AUTOSAR XML (schema 3.2.1)
package /TERootContainer
  composition type ManPW
    8 x require port:
      ManPW_cls_unlock: required-interface=cls_unlock
      ManPW_cls_lock: required-interface=cls_lock
      ManPW_fp_off: required-interface=fp_off
      ManPW_fp_on: required-interface=fp_on
      ManPW_pw_pos_dn: required-interface=pw_but_dn
      ManPW_pw_pos_up: required-interface=pw_but_up
      ManPW_pw_but_up: required-interface=pw_pos_up
      ManPW_pw_but_dn: required-interface=pw_pos_dn
    provide port pw_mv_dn: provided-interface=pw_mv_dn
    provide port pw_mv_up: provided-interface=pw_mv_up
  composition type Power_Window
    8 x require port:
      PW_cls_unlock: required-interface=cls_unlock
      PW_cls_lock: required-interface=cls_lock
      PW_fp_off: required-interface=fp_off
      PW_pw_pos_dn: required-interface=pw_pos_dn
      PW_fp_on: required-interface=fp_on
      PW_pw_pos_up: required-interface=pw_pos_up
      PW_pw_but_up: required-interface=pw_but_up
      PW_pw_but_dn: required-interface=pw_but_dn
    5 x provide port:
      PW_pw_auto_mv_stop: provided-interface=pw_auto_mv_stop
      PW_pw_auto_mv_up: provided-interface=pw_auto_mv_up
      PW_pw_auto_mv_dn: provided-interface=pw_auto_mv_dn
      PW_pw_mv_dn: provided-interface=pw_mv_dn
      PW_pw_mv_up: provided-interface=pw_mv_up
    component ManPW: type=ManPW
    component AutoPW: type=AutoPW
    delegate AutoPW.pw_auto_mv_stop <-> outer port PW_pw_auto_mv_stop
    delegate AutoPW.pw_auto_mv_up <-> outer port PW_pw_auto_mv_up
    delegate AutoPW.pw_auto_mv_dn <-> outer port PW_pw_auto_mv_dn
    delegate ManPW.pw_mv_dn <-> outer port PW_pw_mv_dn
    delegate ManPW.pw_mv_up <-> outer port PW_pw_mv_up
    delegate AutoPW.AUtoPW_cls_unlock <-> outer port PW_cls_unlock
    delegate AutoPW.AutoPW_cls_lock <-> outer port PW_cls_lock
    delegate AutoPW.AutoPW_fp_off <-> outer port PW_fp_off
    delegate AutoPW.AutoPW_fp_on <-> outer port PW_fp_on
    delegate AutoPW.AutoPW_pw_but_dn <-> outer port PW_pw_pos_dn
    delegate AutoPW.AutpPW_pw_but_up <-> outer port PW_pw_pos_up
    delegate AutoPW.AutoPW_pw_pos_up <-> outer port PW_pw_but_up
    delegate AutoPW.AutoPW_pw_pos_dn <-> outer port PW_pw_but_dn
    delegate ManPW.ManPW_cls_unlock <-> outer port PW_cls_unlock
    delegate ManPW.ManPW_cls_lock <-> outer port PW_cls_lock
    delegate ManPW.ManPW_fp_off <-> outer port PW_fp_off
    delegate ManPW.ManPW_fp_on <-> outer port PW_fp_on
    delegate ManPW.ManPW_pw_but_dn <-> outer port PW_pw_pos_dn
    delegate ManPW.ManPW_pw_but_up <-> outer port PW_pw_pos_up
    delegate ManPW.ManPW_pw_pos_up <-> outer port PW_pw_but_up
    delegate ManPW.ManPW_pw_pos_dn <-> outer port PW_pw_but_dn
  composition type System_Software_Architecture  # System Software Architecture
    24 x component:
      Power_Window: type=Power_Window
      LED_CentralLockingSystem: type=LED_CentralLockingSystem
      LED_FingerProtection: type=LED_FingerProtection
      LED_AutomaticPowerWindow: type=LED_AutomaticPowerWindow
      LED_ManualPowerWindow: type=LED_ManualPowerWindow
      HumanMachineInterface: type=HumanMachineInterface
      CentralLockingSystem: type=CentralLockingSystem
      RemoteControlKeyController: type=RemoteControlKeyController
      FingerProtection: type=FingerProtection
      PW_Remote_Control: type=PW_Remote_Control
      Remote_Cotroll_Key: type=Remote_Cotroll_Key
      PW_Button_DN: type=PW_Button_DN
      PW_Button_UP: type=PW_Button_UP
      LED_PW_CLS_UP: type=LED_PW_CLS_UP
      LED_PW_down: type=LED_PW_down
      LED_PW_UP: type=LED_PW_UP
      LED_FP: type=LED_FP
      Finger_Sensor_SWA: type=Finger_Sensor_SWA
      PW_pos_Sensor: type=PW_pos_Sensor
      Car_locking_system: type=Car_locking_system
      door_sensor: type=door_sensor
      driving_sensor: type=driving_sensor
      Key_Pos_Sensor: type=Key_Pos_Sensor
      CLS_LED: type=CLS_LED
    connect .PW_pw_mv_dn -> LED_ManualPowerWindow.pw_mv_dn
    connect .PW_pw_mv_up -> LED_ManualPowerWindow.pw_mv_up
    connect .PW_pw_auto_mv_dn -> LED_AutomaticPowerWindow.pw_auto_mv_dn  # PW_to_LED_AutoPW_pw_auto_mv_dn
    connect .PW_pw_auto_mv_up -> LED_AutomaticPowerWindow.pw_auto_mv_up  # PW_to_LED_AutpPW_pw_auto_mv_up
    connect .PW_pw_auto_mv_stop -> LED_AutomaticPowerWindow.pw_auto_mv_stop  # PW_to_LED_AutpPW_pw_auto_mv_stop
    connect PW_pos_Sensor.pw_pos_dn -> .PW_pw_pos_dn
    connect PW_pos_Sensor.pw_pos_up -> .PW_pw_pos_up
    connect HumanMachineInterface.pw_but_up -> .PW_pw_but_up
    connect FingerProtection.fp_off -> .PW_fp_off
    connect FingerProtection.fp_on -> .PW_fp_on
    connect CentralLockingSystem.cls_unlock -> .PW_cls_unlock
    connect CentralLockingSystem.cls_lock -> .PW_cls_lock
    connect RemoteControlKeyController.pw_but_dn -> .PW_pw_but_dn
    connect RemoteControlKeyController.pw_but_up -> .PW_pw_but_up
    connect HumanMachineInterface.pw_but_dn -> .PW_pw_but_dn
    connect RemoteControlKeyController.rck_unlock -> CentralLockingSystem.rck_unlock
    connect RemoteControlKeyController.rck_lock -> CentralLockingSystem.rck_lock
    connect door_sensor.door_open -> CentralLockingSystem.door_open
    connect door_sensor.door_open -> RemoteControlKeyController.door_open  # Door_Sensor_to_RCKC_door_open
    connect LED_AutomaticPowerWindow.led_pw_dn_off -> LED_PW_down.led_off  # LED_AUTOPW_to_LED_PW_down_off
    connect LED_AutomaticPowerWindow.led_pw_dn_on -> LED_PW_down.led_on
    connect LED_ManualPowerWindow.led_pw_dn_on -> LED_PW_down.led_on
    connect LED_AutomaticPowerWindow.led_pw_cls_up_on -> LED_PW_CLS_UP.led_on  # LED_AUTOPW_to_LED_PW_CLS_UP_on
    connect LED_AutomaticPowerWindow.led_pw_cls_up_off -> LED_PW_CLS_UP.led_off  # LED_AUTOPW_to_LED_PW_CLS_UP_off
    connect LED_ManualPowerWindow.led_pw_dn_off -> LED_PW_down.led_off
    connect LED_ManualPowerWindow.led_pw_up_off -> LED_PW_UP.led_off
    connect LED_ManualPowerWindow.led_pw_up_on -> LED_PW_UP.led_on
    connect LED_AutomaticPowerWindow.led_pw_up_off -> LED_PW_UP.led_off
    connect LED_AutomaticPowerWindow.led_pw_up_on -> LED_PW_UP.led_on
    connect LED_FingerProtection.led_fp_off -> LED_FP.led_fp_off  # LED_Fingerprotection_to_LED_FP_off
    connect LED_FingerProtection.led_fp_on -> LED_FP.led_fp_on  # LED_Fingerprotection_to_LED_FP_on
    connect Finger_Sensor_SWA.finger_detected -> FingerProtection.finger_detected  # Finger_Snesor_to_FP_finger_detected
    connect Key_Pos_Sensor.key_pos_unlock -> CentralLockingSystem.key_pos_unlock
    connect Key_Pos_Sensor.key_pos_lock -> CentralLockingSystem.key_pos_lock
    connect driving_sensor.car_drives -> CentralLockingSystem.car_drives  # Drinving_Sensor_to_CLS_car_drives
    connect PW_Remote_Control.pw_but_down -> RemoteControlKeyController.pw_rm_dn
    connect PW_Remote_Control.pw_but_up -> RemoteControlKeyController.pw_rm_up
    connect Remote_Cotroll_Key.rck_timer -> RemoteControlKeyController.time_rck_sf_elapsed
    connect Remote_Cotroll_Key.rck_but_unlock -> RemoteControlKeyController.rck_but_unlock
    connect Remote_Cotroll_Key.rck_but_lock -> RemoteControlKeyController.rck_but_lock
    connect PW_Button_DN.pw_but_released -> HumanMachineInterface.release_pw_but_dn
    connect PW_Button_DN.pw_but_pressed -> HumanMachineInterface.pw_but_mv_dn
    connect PW_Button_UP.pw_but_released -> HumanMachineInterface.release_pw_but_up
    connect PW_Button_UP.pw_but_pressed -> HumanMachineInterface.pw_but_mv_up
    connect CentralLockingSystem.car_unlock -> Car_locking_system.car_unlock
    connect CentralLockingSystem.car_lock -> Car_locking_system.car_lock
    connect LED_CentralLockingSystem.led_cls_off -> CLS_LED.led_cls_off
    connect LED_CentralLockingSystem.led_cls_on -> CLS_LED.led_cls_on
    connect HumanMachineInterface.release_pw_but -> LED_ManualPowerWindow.release_pw_but  # HMI_to_LED_ManPW_release_pw_but
    connect CentralLockingSystem.cls_lock -> LED_AutomaticPowerWindow.cls_lock
    connect CentralLockingSystem.cls_unlock -> LED_AutomaticPowerWindow.cls_unlock
    connect FingerProtection.fp_off -> LED_FingerProtection.fp_off
    connect FingerProtection.fp_on -> LED_FingerProtection.fp_on
    connect CentralLockingSystem.cls_lock -> LED_CentralLockingSystem.cls_lock
    connect CentralLockingSystem.cls_unlock -> LED_CentralLockingSystem.cls_unlock
    connect HumanMachineInterface.pw_but_dn -> FingerProtection.pw_but_dn
package /SystemInformation
  system System_System_Software_Architecture: fibex-element=[ECU2_HMI, ECU1_Doorsystem, CLS_ECU4, LED_PW_Up, LED_PW_DN, LED_PW_CLS, LED_FP, LED_CLS, Car_Locking_System, Remote_Control_Key, RCK_PW_Buttons, PW_Position_Sensor, PW_But_UP, PW_But_DN, Key_Pos_Sensor, Finger_Sensor_HW, Driving_Snesor, Door_Sensor], pnc-vector-length=0, pnc-vector-offset=0
    mapping Mapping
      sw-impl-mappings:
        9 x swc to impl mapping:
          swcMapping_FingerProtection: component-implementation=Impl_FingerProtection, component=System_Software_Architecture.FingerProtection
          swcMapping_LED_AutomaticPowe: component-implementation=Impl_LED_AutomaticPowerWindo, component=System_Software_Architecture.LED_AutomaticPowerWindow
          swcMapping_RemoteControlKeyC: component-implementation=Impl_RemoteControlKeyControl, component=System_Software_Architecture.RemoteControlKeyController
          swcMapping_LED_FingerProtect: component-implementation=Impl_LED_FingerProtection, component=System_Software_Architecture.LED_FingerProtection
          swcMapping_LED_ManualPowerWi: component-implementation=Impl_LED_ManualPowerWindow, component=System_Software_Architecture.LED_ManualPowerWindow
          swcMapping_AutoPW: component-implementation=Impl_AutoPW, component=System_Software_Architecture.Power_Window.AutoPW
          swcMapping_HumanMachineInter: component-implementation=Impl_HumanMachineInterface, component=System_Software_Architecture.HumanMachineInterface
          swcMapping_LED_CentralLockin: component-implementation=Impl_LED_CentralLockingSyste, component=System_Software_Architecture.LED_CentralLockingSystem
          swcMapping_CentralLockingSys: component-implementation=Impl_CentralLockingSystem, component=System_Software_Architecture.CentralLockingSystem
      sw-mappings:
        17 x swc to ecu mapping:
          ECU2_HMI_FBMapping: ecu-instance=ECU2_HMI
            component:
              System_Software_Architecture.LED_AutomaticPowerWindow
              System_Software_Architecture.LED_FingerProtection
              System_Software_Architecture.LED_ManualPowerWindow
              System_Software_Architecture.LED_CentralLockingSystem
              System_Software_Architecture.HumanMachineInterface
          PW_But_UP_FBMapping: component=System_Software_Architecture.PW_Button_UP, ecu-instance=PW_But_UP
          ECU1_Doorsystem_FBMapping: ecu-instance=ECU1_Doorsystem
            component:
              System_Software_Architecture.Power_Window.AutoPW
              System_Software_Architecture.Power_Window.ManPW
              System_Software_Architecture.FingerProtection
          PW_But_DN_FBMapping: component=System_Software_Architecture.PW_Button_DN, ecu-instance=PW_But_DN
          Driving_Snesor_FBMapping: component=System_Software_Architecture.driving_sensor, ecu-instance=Driving_Snesor
          Remote_Control_Key_FBMapping: component=System_Software_Architecture.Remote_Cotroll_Key, ecu-instance=Remote_Control_Key
          PW_Position_Sensor_FBMapping: component=System_Software_Architecture.PW_pos_Sensor, ecu-instance=PW_Position_Sensor
          Car_Locking_System_FBMapping: component=System_Software_Architecture.Car_locking_system, ecu-instance=Car_Locking_System
          CLS_ECU4_FBMapping: ecu-instance=CLS_ECU4
            component:
              System_Software_Architecture.CentralLockingSystem
              System_Software_Architecture.RemoteControlKeyController
          Door_Sensor_FBMapping: component=System_Software_Architecture.door_sensor, ecu-instance=Door_Sensor
          LED_CLS_FBMapping: component=[System_Software_Architecture.CLS_LED, System_Software_Architecture.LED_PW_CLS_UP], ecu-instance=LED_CLS
          Key_Pos_Sensor_FBMapping: component=System_Software_Architecture.Key_Pos_Sensor, ecu-instance=Key_Pos_Sensor
          LED_FP_FBMapping: component=System_Software_Architecture.LED_FP, ecu-instance=LED_FP
          Finger_Sensor_HW_FBMapping: component=System_Software_Architecture.Finger_Sensor_SWA, ecu-instance=Finger_Sensor_HW
          LED_PW_Up_FBMapping: component=System_Software_Architecture.LED_PW_UP, ecu-instance=LED_PW_Up
          RCK_PW_Buttons_FBMapping: component=System_Software_Architecture.PW_Remote_Control, ecu-instance=RCK_PW_Buttons
          LED_PW_DN_FBMapping: component=System_Software_Architecture.LED_PW_down, ecu-instance=LED_PW_DN
    software composition System_Software_Architecture: software-composition=System_Software_Architecture
package /Software_Types  # Software Types
package /Software_Types/Interface_Types  # Interface Types
package /Software_Types/Interface_Types/Sender__Receiver_Interfaces  # Sender-/Receiver Interfaces
package /Software_Types/Interface_Types/Sender__Receiver_Interfaces/BCS_Basic/signal_output
  10 x sender receiver interface:
    led_cls_off
    led_cls_on
    led_pw_cls_up_off
    led_pw_cls_up_on
    led_pw_dn_off
    led_pw_dn_on
    led_pw_up_off
    led_pw_up_on
    car_unlock
    car_lock
package /Software_Types/Interface_Types/Sender__Receiver_Interfaces/BCS_Basic/signal_internal
  14 x sender receiver interface:
    fp_on
    fp_off
    pw_mv_up
    pw_mv_dn
    pw_auto_mv_up
    pw_auto_mv_stop
    pw_auto_mv_dn
    release_pw_but
    cls_unlock
    cls_lock
    rck_unlock
    rck_lock
      data rck_lock
    pw_but_up
    pw_but_dn
package /Software_Types/Interface_Types/Sender__Receiver_Interfaces/BCS_Basic/signal_input
  16 x sender receiver interface:
    finger_detected
    release_pw_but_dn
    release_pw_but_up
    pw_but_mv_up
    pw_but_mv_dn
    car_drives
    pw_rm_dn
    pw_rm_up
    rck_but_unlock
    rck_but_lock
    time_rck_sf_elapsed
    door_open
    key_pos_unlock
    key_pos_lock
    pw_pos_up
    pw_pos_dn
package /Software_Types/Block_Types  # Block Types
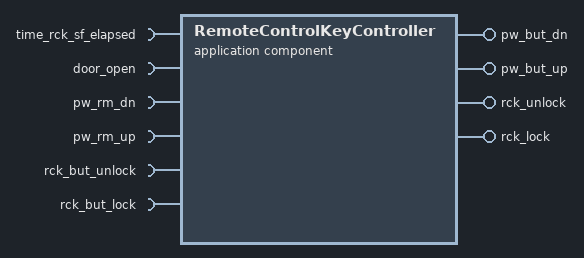
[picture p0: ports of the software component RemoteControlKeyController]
  application software component type RemoteControlKeyController
    6 x require port:
      time_rck_sf_elapsed: required-interface=time_rck_sf_elapsed
      door_open: required-interface=door_open
      pw_rm_dn: required-interface=pw_rm_dn
      pw_rm_up: required-interface=pw_rm_up
      rck_but_unlock: required-interface=rck_but_unlock
      rck_but_lock: required-interface=rck_but_lock
    4 x provide port:
      pw_but_dn: provided-interface=pw_but_dn
      pw_but_up: provided-interface=pw_but_up
      rck_unlock: provided-interface=rck_unlock
      rck_lock: provided-interface=rck_lock
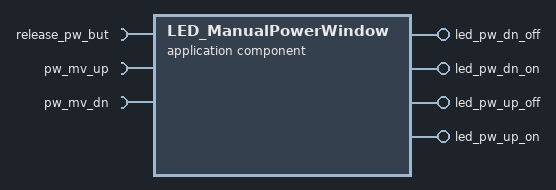
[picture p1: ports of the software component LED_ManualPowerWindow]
  application software component type LED_ManualPowerWindow
    require port release_pw_but: required-interface=release_pw_but
    require port pw_mv_up: required-interface=pw_mv_up
    require port pw_mv_dn: required-interface=pw_mv_dn
    4 x provide port:
      led_pw_dn_off: provided-interface=led_pw_dn_off
      led_pw_dn_on: provided-interface=led_pw_dn_on
      led_pw_up_off: provided-interface=led_pw_up_off
      led_pw_up_on: provided-interface=led_pw_up_on
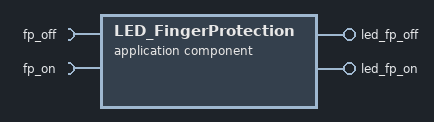
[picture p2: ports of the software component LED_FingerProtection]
  application software component type LED_FingerProtection
    require port fp_off: required-interface=fp_off
    require port fp_on: required-interface=fp_on
    provide port led_fp_off
    provide port led_fp_on
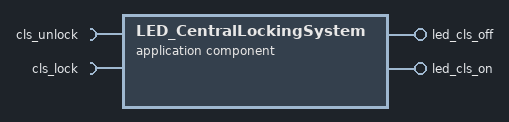
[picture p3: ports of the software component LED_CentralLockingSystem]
  application software component type LED_CentralLockingSystem
    require port cls_unlock: required-interface=cls_unlock
    require port cls_lock: required-interface=cls_lock
    provide port led_cls_off: provided-interface=led_cls_off
    provide port led_cls_on: provided-interface=led_cls_on
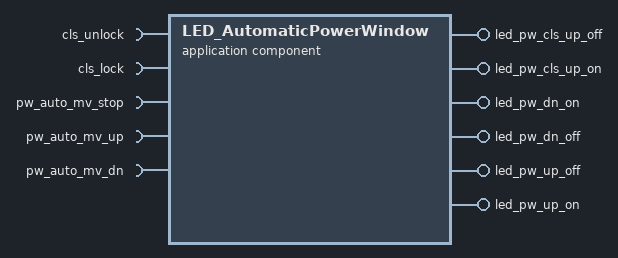
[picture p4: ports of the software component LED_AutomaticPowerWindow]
  application software component type LED_AutomaticPowerWindow
    5 x require port:
      cls_unlock: required-interface=cls_unlock
      cls_lock: required-interface=cls_lock
      pw_auto_mv_stop: required-interface=pw_auto_mv_stop
      pw_auto_mv_up: required-interface=pw_auto_mv_up
      pw_auto_mv_dn: required-interface=pw_auto_mv_dn
    6 x provide port:
      led_pw_cls_up_off: provided-interface=led_pw_cls_up_off
      led_pw_cls_up_on: provided-interface=led_pw_cls_up_on
      led_pw_dn_on: provided-interface=led_pw_dn_on
      led_pw_dn_off: provided-interface=led_pw_dn_off
      led_pw_up_off: provided-interface=led_pw_up_off
      led_pw_up_on: provided-interface=led_pw_up_on
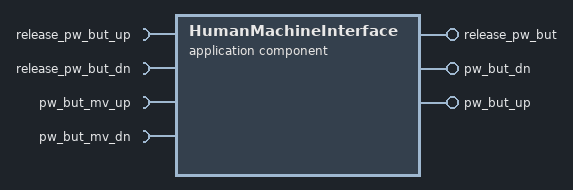
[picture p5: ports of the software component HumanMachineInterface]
  application software component type HumanMachineInterface
    4 x require port:
      release_pw_but_up: required-interface=release_pw_but_up
      release_pw_but_dn: required-interface=release_pw_but_dn
      pw_but_mv_up: required-interface=pw_but_mv_up
      pw_but_mv_dn: required-interface=pw_but_mv_dn
    provide port release_pw_but: provided-interface=release_pw_but
    provide port pw_but_dn: provided-interface=pw_but_dn
    provide port pw_but_up: provided-interface=pw_but_up
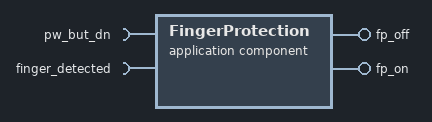
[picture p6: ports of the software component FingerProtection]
  application software component type FingerProtection
    require port pw_but_dn: required-interface=pw_but_dn
    require port finger_detected: required-interface=finger_detected
    provide port fp_off: provided-interface=fp_off
    provide port fp_on: provided-interface=fp_on
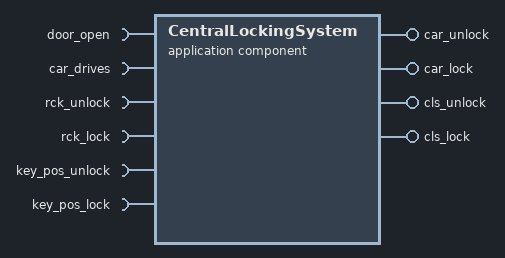
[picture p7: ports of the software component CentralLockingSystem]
  application software component type CentralLockingSystem
    6 x require port:
      door_open: required-interface=door_open
      car_drives: required-interface=car_drives
      rck_unlock: required-interface=rck_unlock
      rck_lock: required-interface=rck_lock
      key_pos_unlock: required-interface=key_pos_unlock
      key_pos_lock: required-interface=key_pos_lock
    4 x provide port:
      car_unlock: provided-interface=car_unlock
      car_lock: provided-interface=car_lock
      cls_unlock: provided-interface=cls_unlock
      cls_lock: provided-interface=cls_lock
  8 x internal behavior:
    LED_CentralLockingSystem_1
    LED_FingerProtection_1
    LED_AutomaticPowerWindow_1
    LED_ManualPowerWindow_1
    HumanMachineInterface_1
    CentralLockingSystem_1
    RemoteControlKeyController_1
    FingerProtection_1
package /Software_Types/Block_Types/PowerWindow_PW_  # PowerWindow(PW)
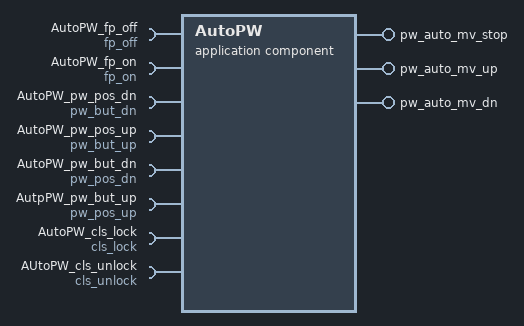
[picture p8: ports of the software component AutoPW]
  application software component type AutoPW
    8 x require port:
      AutoPW_fp_off: required-interface=fp_off
      AutoPW_fp_on: required-interface=fp_on
      AutoPW_pw_pos_dn: required-interface=pw_but_dn
      AutoPW_pw_pos_up: required-interface=pw_but_up
      AutoPW_pw_but_dn: required-interface=pw_pos_dn
      AutpPW_pw_but_up: required-interface=pw_pos_up
      AutoPW_cls_lock: required-interface=cls_lock
      AUtoPW_cls_unlock: required-interface=cls_unlock
    provide port pw_auto_mv_stop: provided-interface=pw_auto_mv_stop
    provide port pw_auto_mv_up: provided-interface=pw_auto_mv_up
    provide port pw_auto_mv_dn: provided-interface=pw_auto_mv_dn
  internal behavior AutoPW_1
package /Software_Types/Block_Types/Sensor_Types  # Sensor Types
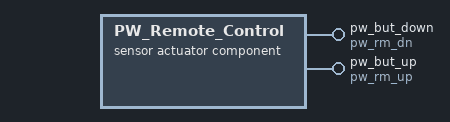
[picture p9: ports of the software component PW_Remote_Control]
  sensor actuator software component type PW_Remote_Control
    provide port pw_but_down: provided-interface=pw_rm_dn
    provide port pw_but_up: provided-interface=pw_rm_up
  sensor actuator software component type Remote_Cotroll_Key
    provide port rck_timer: provided-interface=time_rck_sf_elapsed
    provide port rck_but_unlock: provided-interface=rck_but_unlock
    provide port rck_but_lock: provided-interface=rck_but_lock
  sensor actuator software component type PW_Button_DN
    provide port pw_but_released: provided-interface=release_pw_but_dn
    provide port pw_but_pressed: provided-interface=pw_but_mv_dn
  sensor actuator software component type PW_Button_UP
    provide port pw_but_released: provided-interface=release_pw_but_up
    provide port pw_but_pressed: provided-interface=pw_but_mv_up
  sensor actuator software component type Finger_Sensor_SWA
    provide port finger_detected: provided-interface=finger_detected
  sensor actuator software component type PW_pos_Sensor
    provide port pw_pos_dn: provided-interface=pw_pos_dn
    provide port pw_pos_up: provided-interface=pw_pos_up
  sensor actuator software component type door_sensor
    provide port door_open: provided-interface=door_open
  sensor actuator software component type driving_sensor
    provide port car_drives: provided-interface=car_drives
  sensor actuator software component type Key_Pos_Sensor
    provide port key_pos_unlock: provided-interface=key_pos_unlock
    provide port key_pos_lock: provided-interface=key_pos_lock
package /Software_Types/Block_Types/Actuator_Types  # Actuator Types
  sensor actuator software component type LED_PW_CLS_UP
    require port led_off: required-interface=led_pw_cls_up_off
    require port led_on: required-interface=led_pw_cls_up_on
  sensor actuator software component type LED_PW_down
    require port led_off: required-interface=led_pw_dn_off
    require port led_on: required-interface=led_pw_dn_on
  sensor actuator software component type LED_PW_UP
    require port led_off: required-interface=led_pw_up_off
    require port led_on: required-interface=led_pw_up_on
  sensor actuator software component type LED_FP
    require port led_fp_off
    require port led_fp_on
  sensor actuator software component type Car_locking_system
    require port car_unlock: required-interface=car_unlock
    require port car_lock: required-interface=car_lock
  sensor actuator software component type CLS_LED
    require port led_cls_off: required-interface=led_cls_off
    require port led_cls_on: required-interface=led_cls_on
package /Data_Types  # Data Types
package /Components/Components/Komponentendiagramm/BCS_Basic
  18 x ecu instance, all with com-configuration-id=0, com-processing-period=0.001, com-processing-period-gw=0.0, com-processing-period-rx=0.0, diagnostic-address=0, pdu-r-configuration-id=0, sleep-mode-supported=false, wake-up-over-bus-supported=false:
    ECU2_HMI
      communication connector HMI_Inputbus_LED: nm-address=0
      communication connector HMI_Bus_Connector: nm-address=0
    ECU1_Doorsystem
      communication connector Doorsystem_Outputbus: nm-address=0
      communication connector Doorsystem_Input_Bus_Connect: nm-address=0  # Doorsystem_Input_Bus_Connector
    CLS_ECU4
      communication connector CLS_ECU_Outputbus: nm-address=0
    LED_PW_Up: category=Actuator
    LED_PW_DN: category=Actuator
    LED_PW_CLS: category=Actuator
    LED_FP: category=Actuator
    LED_CLS: category=Actuator
    Car_Locking_System: category=Actuator
    Remote_Control_Key: category=Sensor
    RCK_PW_Buttons: category=Sensor
    PW_Position_Sensor: category=Sensor
    PW_But_UP: category=Sensor
    PW_But_DN: category=Sensor
    Key_Pos_Sensor: category=Sensor
    Finger_Sensor_HW: category=Sensor
    Driving_Snesor: category=Sensor
    Door_Sensor: category=Sensor
package /Implementation
  9 x swc implementation, all with sw-major-version=0, sw-minor-version=0, sw-patch-version=0, vendor-id=0:
    Impl_CentralLockingSystem: behavior=CentralLockingSystem_1
    Impl_AutoPW: behavior=AutoPW_1
    Impl_RemoteControlKeyControl: behavior=RemoteControlKeyController_1
    Impl_HumanMachineInterface: behavior=HumanMachineInterface_1
    Impl_LED_FingerProtection: behavior=LED_FingerProtection_1
    Impl_LED_CentralLockingSyste: behavior=LED_CentralLockingSystem_1
    Impl_LED_ManualPowerWindow: behavior=LED_ManualPowerWindow_1
    Impl_LED_AutomaticPowerWindo: behavior=LED_AutomaticPowerWindow_1
    Impl_FingerProtection: behavior=FingerProtection_1
